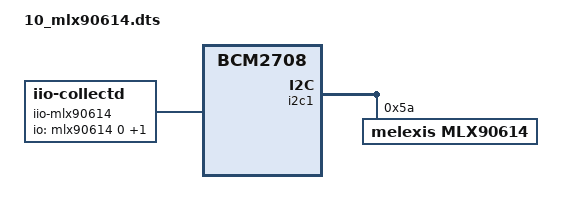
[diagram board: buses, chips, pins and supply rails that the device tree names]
/dts-v1/;
/plugin/;

/ {
  compatible = "brcm,bcm2708"; /* probably will soon be bcm2835? */

  fragment@0 {
    target = <&i2c1>; /* NOTE: cannot use i2c_arm here! */
    __overlay__ {
      #address-cells = <1>; /* 1 for i2c devices */
      #size-cells = <0>;    /* 0 for i2c devices */
      status = "okay";

      mlx90614: mlx90614@5a {
        /* i2c */
        compatible = "melexis,mlx90614"; /* NOTE: in backports. This driver gives RAW values only. */
        reg = <0x5a>;
        status = "okay";

        /* iio */
        #io-channel-cells = <1>; /* 1 for multiple channels */

        /* iio/temperature/mlx90614 special config */
        /* (NONE) */
      };
    };
  };

  /* iio-hwmon bridge (modified version) */
  /* This mirrors iio channels to hwmon, which can be hooked to collectd. */
  fragment@1 {
    target-path = "/";
    __overlay__ {
      iio-mlx90614 {
        compatible = "iio-collectd";
        /* NOTE: some variant has 2 object channels. Add "<&mlx90614 2>" and turn names into "Object 1" and "Object 2". */
        io-channels = <&mlx90614 0>, <&mlx90614 1>;
        io-channel-names = "Ambient", "Object";
      };
    };
  };
};
